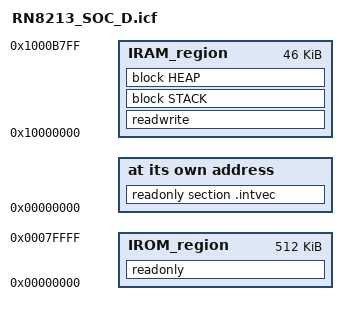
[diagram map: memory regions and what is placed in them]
/*
 * To use stack sealing, add "__USE_STACK_SEAL=1" to the linker Configuration file symbol box, or
 * add "--config_def __USE_STACK_SEAL=1" to the linker command line
 */
/*###ICF### Section handled by ICF editor, don't touch! ****/
/*-Editor annotation file-*/
/* IcfEditorFile="$TOOLKIT_DIR$\config\ide\IcfEditor\cortex_v1_1.xml" */
/*-Specials-*/
define symbol __ICFEDIT_intvec_start__ = 0x00000000;
/*-Memory Regions-*/
define symbol __ICFEDIT_region_IROM1_start__ = 0x00000000;
define symbol __ICFEDIT_region_IROM1_end__   = 0x0007FFFF;
define symbol __ICFEDIT_region_IROM2_start__ = 0x0;
define symbol __ICFEDIT_region_IROM2_end__   = 0x0;
define symbol __ICFEDIT_region_EROM1_start__ = 0x0;
define symbol __ICFEDIT_region_EROM1_end__   = 0x0;
define symbol __ICFEDIT_region_EROM2_start__ = 0x0;
define symbol __ICFEDIT_region_EROM2_end__   = 0x0;
define symbol __ICFEDIT_region_EROM3_start__ = 0x0;
define symbol __ICFEDIT_region_EROM3_end__   = 0x0;
define symbol __ICFEDIT_region_IRAM1_start__ = 0x10000000;
define symbol __ICFEDIT_region_IRAM1_end__   = 0x1000B7FF;
define symbol __ICFEDIT_region_IRAM2_start__ = 0x0;
define symbol __ICFEDIT_region_IRAM2_end__   = 0x0;
define symbol __ICFEDIT_region_ERAM1_start__ = 0x0;
define symbol __ICFEDIT_region_ERAM1_end__   = 0x0;
define symbol __ICFEDIT_region_ERAM2_start__ = 0x0;
define symbol __ICFEDIT_region_ERAM2_end__   = 0x0;
define symbol __ICFEDIT_region_ERAM3_start__ = 0x0;
define symbol __ICFEDIT_region_ERAM3_end__   = 0x0;
/*-Sizes-*/
define symbol __ICFEDIT_size_cstack__ = 0x1700;
define symbol __ICFEDIT_size_heap__   = 0x2E00;
/**** End of ICF editor section. ###ICF###*/

define memory mem with size = 4G;
define region IROM_region   =   mem:[from __ICFEDIT_region_IROM1_start__ to __ICFEDIT_region_IROM1_end__]
                              | mem:[from __ICFEDIT_region_IROM2_start__ to __ICFEDIT_region_IROM2_end__];
define region EROM_region   =   mem:[from __ICFEDIT_region_EROM1_start__ to __ICFEDIT_region_EROM1_end__]
                              | mem:[from __ICFEDIT_region_EROM2_start__ to __ICFEDIT_region_EROM2_end__]
                              | mem:[from __ICFEDIT_region_EROM3_start__ to __ICFEDIT_region_EROM3_end__];
define region IRAM_region   =   mem:[from __ICFEDIT_region_IRAM1_start__ to __ICFEDIT_region_IRAM1_end__]
                              | mem:[from __ICFEDIT_region_IRAM2_start__ to __ICFEDIT_region_IRAM2_end__];
define region ERAM_region   =   mem:[from __ICFEDIT_region_ERAM1_start__ to __ICFEDIT_region_ERAM1_end__]
                              | mem:[from __ICFEDIT_region_ERAM2_start__ to __ICFEDIT_region_ERAM2_end__]
                              | mem:[from __ICFEDIT_region_ERAM3_start__ to __ICFEDIT_region_ERAM3_end__];

if (isdefinedsymbol(__USE_STACK_SEAL)) {
  define symbol __STACKSEAL_SIZE = 8;
  define block CSTACK  with alignment = 8, size = __ICFEDIT_size_cstack__ - __STACKSEAL_SIZE  { };
  define block STACKSEAL with size = __STACKSEAL_SIZE { };
  keep	 { block STACKSEAL };
  define block STACK	 with fixed order { block CSTACK, block STACKSEAL };
} else {
  define block CSTACK    with alignment = 8, size = __ICFEDIT_size_cstack__   { };
  define block STACK	 with fixed order { block CSTACK };
}

define block HEAP      with alignment = 8, size = __ICFEDIT_size_heap__     { };

do not initialize  { section .noinit };
initialize by copy { readwrite };
if (isdefinedsymbol(__USE_DLIB_PERTHREAD))
{
  // Required in a multi-threaded application
  initialize by copy with packing = none { section __DLIB_PERTHREAD };
}

place at address mem:__ICFEDIT_intvec_start__ { readonly section .intvec };

place in IROM_region  { readonly };
place in EROM_region  { readonly section application_specific_ro };
place in IRAM_region  { readwrite, block STACK, block HEAP };
place in ERAM_region  { readwrite section application_specific_rw };
